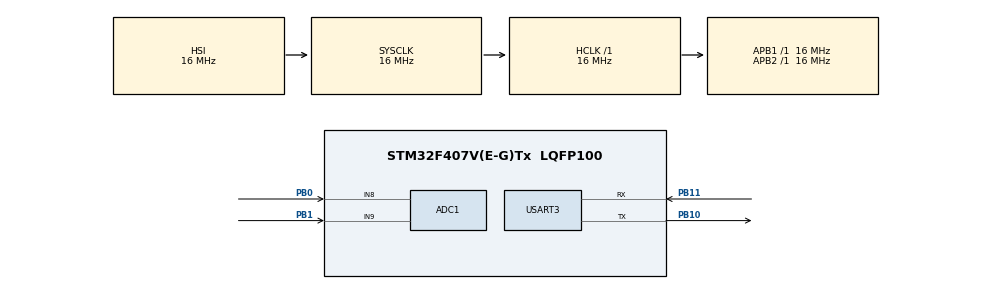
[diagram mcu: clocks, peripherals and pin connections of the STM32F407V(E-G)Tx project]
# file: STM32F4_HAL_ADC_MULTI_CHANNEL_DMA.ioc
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ADC1.Channel-0\#ChannelRegularConversion=ADC_CHANNEL_8
ADC1.Channel-1\#ChannelRegularConversion=ADC_CHANNEL_9
ADC1.ContinuousConvMode=ENABLE
ADC1.DMAContinuousRequests=ENABLE
ADC1.NbrOfConversion=2
ADC1.NbrOfConversionFlag=1
ADC1.Rank-0\#ChannelRegularConversion=1
ADC1.Rank-1\#ChannelRegularConversion=2
ADC1.SamplingTime-0\#ChannelRegularConversion=ADC_SAMPLETIME_480CYCLES
ADC1.SamplingTime-1\#ChannelRegularConversion=ADC_SAMPLETIME_480CYCLES
ADC1.ScanConvMode=ENABLE
ADC1.master=1
Dma.ADC1.0.Direction=DMA_PERIPH_TO_MEMORY
Dma.ADC1.0.FIFOMode=DMA_FIFOMODE_DISABLE
Dma.ADC1.0.Instance=DMA2_Stream0
Dma.ADC1.0.MemDataAlignment=DMA_MDATAALIGN_HALFWORD
Dma.ADC1.0.MemInc=DMA_MINC_ENABLE
Dma.ADC1.0.Mode=DMA_CIRCULAR
Dma.ADC1.0.PeriphDataAlignment=DMA_PDATAALIGN_HALFWORD
Dma.ADC1.0.PeriphInc=DMA_PINC_DISABLE
Dma.ADC1.0.Priority=DMA_PRIORITY_LOW
Dma.Request0=ADC1
Mcu.Family=STM32F4
Mcu.Name=STM32F407V(E-G)Tx
Mcu.Package=LQFP100
NVIC.DMA2_Stream0_IRQn=true\:0\:0\:false\:false\:true\:false\:true\:true
NVIC.PriorityGroup=NVIC_PRIORITYGROUP_4
PB0.Signal=ADCx_IN8
PB1.Signal=ADCx_IN9
PB10.Mode=Asynchronous
PB10.Signal=USART3_TX
PB11.Mode=Asynchronous
PB11.Signal=USART3_RX
ProjectManager.HeapSize=0x200
ProjectManager.StackSize=0x400
ProjectManager.TargetToolchain=TrueSTUDIO
RCC.AHBFreq_Value=16000000
RCC.APB1Freq_Value=16000000
RCC.APB2Freq_Value=16000000
RCC.CortexFreq_Value=16000000
RCC.HSE_VALUE=25000000
RCC.HSI_VALUE=16000000
RCC.LSE_VALUE=32768
RCC.SYSCLKFreq_VALUE=16000000
RCC.VCOOutputFreq_Value=192000000
SH.ADCx_IN8.0=ADC1_IN8,IN8
SH.ADCx_IN9.0=ADC1_IN9,IN9
USART3.VirtualMode=VM_ASYNC
board=custom

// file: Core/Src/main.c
/* USER CODE BEGIN Header */
/**
 ******************************************************************************
 * @file           : main.c
 * @brief          : Main program body
 ******************************************************************************
 * @attention
 *
 * Copyright (c) 2022 STMicroelectronics.
 * All rights reserved.
 *
 * This software is licensed under terms that can be found in the LICENSE file
 * in the root directory of this software component.
 * If no LICENSE file comes with this software, it is provided AS-IS.
 *
 ******************************************************************************
 */
/* USER CODE END Header */
#include "main.h"
#include "adc.h"
#include "dma.h"
#include "usart.h"
#include "gpio.h"

/* USER CODE BEGIN PV */
uint16_t adcValArray[2];
char buffer[20];
/* USER CODE END PV */

void SystemClock_Config(void);

int main(void) {

	/* MCU Configuration--------------------------------------------------------*/

	/* Reset of all peripherals, Initializes the Flash interface and the Systick. */
	HAL_Init();

	/* Configure the system clock */
	SystemClock_Config();

	/* Initialize all configured peripherals */
	MX_GPIO_Init();
	MX_DMA_Init();
	MX_ADC1_Init();
	MX_USART3_UART_Init();
	/* USER CODE BEGIN 2 */
	HAL_ADC_Start_DMA(&hadc1, (uint32_t *) adcValArray, 2);
	/* USER CODE END 2 */

	/* Infinite loop */
	while (1) {
		HAL_UART_Transmit(&huart3, (uint8_t *) buffer, sprintf(buffer, "ADC 1: %d\n\r", adcValArray[0]), 200);
		HAL_Delay(500);
		HAL_UART_Transmit(&huart3, (uint8_t *) buffer, sprintf(buffer, "ADC 2: %d\n\r", adcValArray[1]), 200);
		HAL_Delay(500);
	}
}

void SystemClock_Config(void) {
	RCC_OscInitTypeDef RCC_OscInitStruct = { 0 };
	RCC_ClkInitTypeDef RCC_ClkInitStruct = { 0 };

	/** Configure the main internal regulator output voltage
	 */
	__HAL_RCC_PWR_CLK_ENABLE()
	;
	__HAL_PWR_VOLTAGESCALING_CONFIG(PWR_REGULATOR_VOLTAGE_SCALE1);

	/** Initializes the RCC Oscillators according to the specified parameters
	 * in the RCC_OscInitTypeDef structure.
	 */
	RCC_OscInitStruct.OscillatorType = RCC_OSCILLATORTYPE_HSI;
	RCC_OscInitStruct.HSIState = RCC_HSI_ON;
	RCC_OscInitStruct.HSICalibrationValue = RCC_HSICALIBRATION_DEFAULT;
	RCC_OscInitStruct.PLL.PLLState = RCC_PLL_NONE;
	if (HAL_RCC_OscConfig(&RCC_OscInitStruct) != HAL_OK) {
		Error_Handler();
	}

	/** Initializes the CPU, AHB and APB buses clocks
	 */
	RCC_ClkInitStruct.ClockType = RCC_CLOCKTYPE_HCLK | RCC_CLOCKTYPE_SYSCLK
			| RCC_CLOCKTYPE_PCLK1 | RCC_CLOCKTYPE_PCLK2;
	RCC_ClkInitStruct.SYSCLKSource = RCC_SYSCLKSOURCE_HSI;
	RCC_ClkInitStruct.AHBCLKDivider = RCC_SYSCLK_DIV1;
	RCC_ClkInitStruct.APB1CLKDivider = RCC_HCLK_DIV1;
	RCC_ClkInitStruct.APB2CLKDivider = RCC_HCLK_DIV1;

	if (HAL_RCC_ClockConfig(&RCC_ClkInitStruct, FLASH_LATENCY_0) != HAL_OK) {
		Error_Handler();
	}
}

void Error_Handler(void) {
	__disable_irq();
	while (1) {
	}
}
